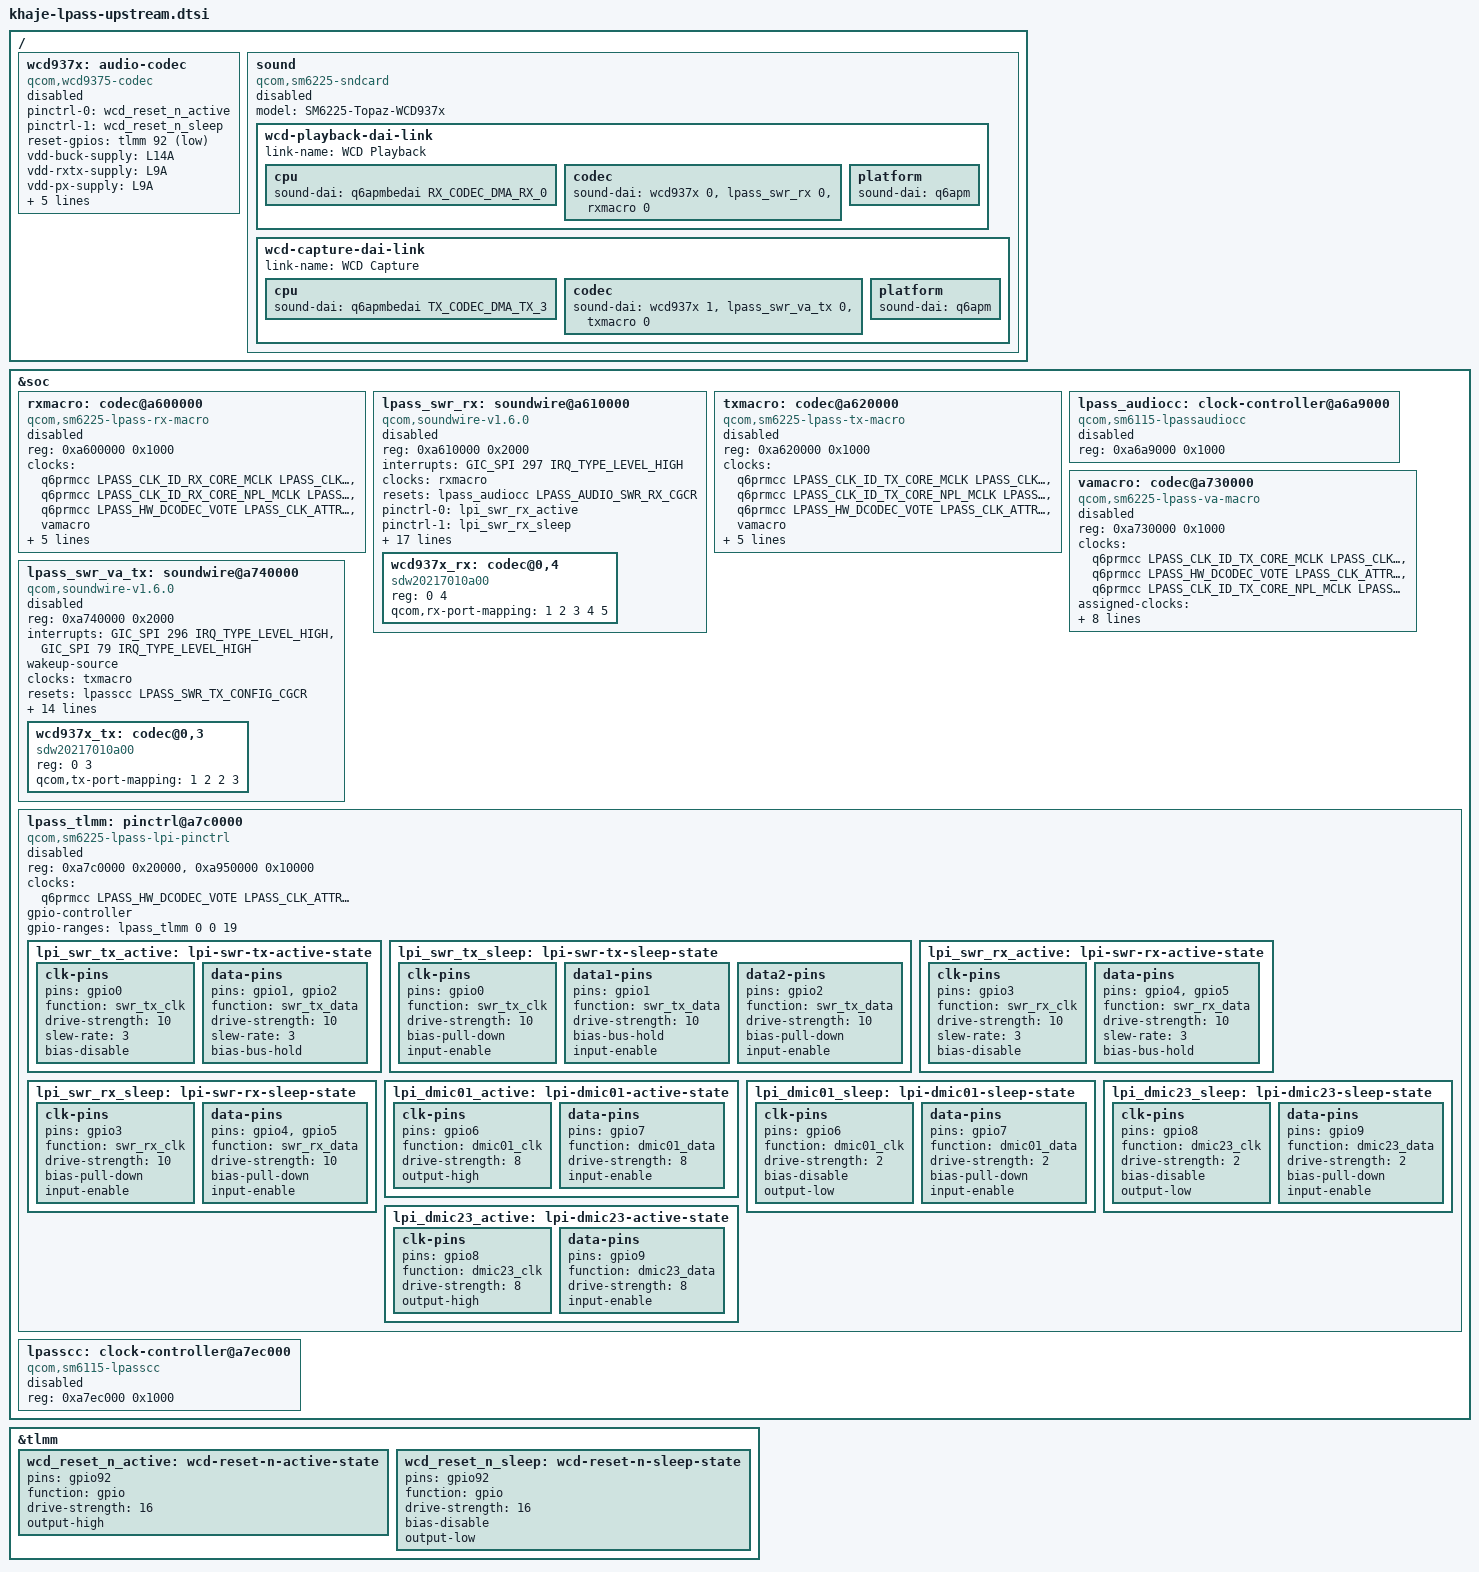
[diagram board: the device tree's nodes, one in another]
/* SPDX-License-Identifier: GPL-2.0-only */
/*
 * DTS DE TESTE — LPASS upstream (macros RX/TX/VA + SoundWire) para o
 * Khaje/topaz.
 *
 * NAO e incluido por nenhuma DTS de producao e nao e encenado por
 * tools/integrate_dts.py (que so copia device-tree/source). Serve para
 * validar estaticamente os providers de reset do patch 0029 e os
 * compatibles/matches de macro do patch 0030 contra as labels reais da
 * arvore encenada, sem ativar probe de macro, SoundWire ou codec.
 * Todos os nos ficam "disabled".
 *
 * Uso manual: incluir depois de khaje.dtsi/khaje-idp-nopmi.dtsi e de
 * khaje-adsp-upstream.dtsi (que define &q6prmcc) numa DTS de teste e
 * compilar com dtc. Nao usar junto do overlay de audio vendor Bengal
 * como modelo de ativacao: os dois descrevem o mesmo hardware LPASS.
 * Auditoria em docs/audio-port-audit.md.
 *
 * Traducao feita neste fragmento:
 *   - MMIO das macros e versao/IRQs/portas logicas SoundWire vem do
 *     overlay vendor Bengal: RX 0xa600000, TX 0xa620000,
 *     VA 0xa730000; SWR RX 0xa610000/SPI 297 e SWR VA_TX
 *     0xa740000/SPI 296+79, ambos qcom,soundwire-v1.6.0;
 *   - a topologia de clocks e os arrays qcom,ports-* seguem o DTS
 *     upstream Agatti/SM6115, trocando apenas o provider legado
 *     &q6afecc pelo &q6prmcc ja modelado no prototipo AudioReach.
 *     Os IDs simbolicos LPASS_CLK_ID_* sao os mesmos e mapeiam no
 *     Q6PRM para RX 0x30e/0x30f e TX 0x30c/0x30d;
 *   - os resets usam os CGCRs do patch 0029. Os offsets 0x98/0x100
 *     conferem com qcom,swrm-hctl-reg = 0xa6a9098/0xa7ec100 do
 *     overlay vendor sobre as bases 0xa6a9000/0xa7ec000;
 *   - VA recebe qcom,dmic-sample-rate = 600000, valor vendor e unico
 *     dos tres drivers que o driver upstream realmente le;
 *   - o patch 0031 modela o LPI TLMM em 0xa7c0000/0xa950000 com os
 *     estados SoundWire ativos/sleep traduzidos do FDT Topaz:
 *     TX em gpio0-2 e RX em gpio3-5, func1 virando
 *     swr_tx e swr_rx, slew-rate 3 e drive-strength 10 ativos.
 *     O clock "audio" usa o voto DCODEC do &q6prmcc, como no
 *     binding SM6115 sobre o provider AudioReach local. Os
 *     estados DMIC gpio6-9 (dmic01/dmic23 clk e data) seguem os
 *     valores active/sleep do FDT e ficam ligados a VA;
 *   - os slaves WCD937x usam os IDs decodificados dos reg vendor
 *     <0x0a 0x01170224> (RX) e <0x0a 0x01170223> (TX): fabricante
 *     0x0217, parte 0x010a, versao 2 e unique-id 4/3, ou seja
 *     codec@0,4 e codec@0,3 com compatible sdw20217010a00. O pai
 *     usa reset no TLMM GPIO 92, supplies L9A (rxtx/px) e L14A
 *     (buck) e micbias 1-3 em 2700 mV do overlay Xiaomi;
 *   - o patch 0032 liga a maquina generica AudioReach sc8280xp ao
 *     compatible qcom,sm6225-sndcard. O no sound abaixo descreve
 *     somente os backends WCD Playback e WCD Capture sobre o
 *     &q6apmbedai, no mesmo formato das placas QCM6490 com WCD9370.
 *
 * Bloqueios conhecidos antes de qualquer ativacao:
 *   - o overlay vendor tambem declara clocks VA dedicados 0x307/0x308,
 *     mas o no VA usa qcom,default-clk-id = <TX_CORE_CLK> e o modelo
 *     upstream SM6115 alimenta VA com TX core/NPL. Essa e uma hipotese
 *     forte de topologia, nao uma prova de runtime no SM6225;
 *   - os estados LPI de DMIC (gpio6-9) sao modelados e ligados a
 *     VA, mas as rotas de microfone/micbias entre VA, TX e WCD e o
 *     ID de backend do link VA seguem abertos; sem isso a VA nao
 *     entra no no sound;
 *   - o pai WCD e modelado como wcd9375 com fallback wcd9370 por
 *     inferencia dos overlays Khaje "nowcd9375"; o FDT Topaz so diz
 *     wcd937x e o driver distingue o chip por registrador, mas a
 *     identidade do silicio nao esta confirmada. O rail upstream
 *     vdd-mic-bias nao foi identificado no Topaz (o vendor lista so
 *     rxtx/px/buck), micbias4 nao e inventado e o map estatico TX
 *     <1 2 2 3> nao reproduz o mapa por canal vendor. Mesmo com a
 *     maquina modelada, sem fechar isso, rotas, amplificadores, o
 *     link VA e a topologia AudioReach do firmware, nao ha card
 *     de som utilizavel;
 *   - o ADSP/GPR/Q6PRM do fragmento vizinho continua desabilitado e
 *     sem boot/probe em hardware. Compilar este DTS nao valida os
 *     votos de clock no firmware nem a enumeracao SoundWire.
 */

#include <dt-bindings/clock/qcom,sm6115-lpasscc.h>
#include <dt-bindings/gpio/gpio.h>
#include <dt-bindings/interrupt-controller/arm-gic.h>
#include <dt-bindings/interrupt-controller/irq.h>
#include <dt-bindings/sound/qcom,q6afe.h>
#include <dt-bindings/sound/qcom,q6dsp-lpass-ports.h>

&soc {
	rxmacro: codec@a600000 {
		compatible = "qcom,sm6225-lpass-rx-macro",
			     "qcom,sm6115-lpass-rx-macro";
		reg = <0xa600000 0x1000>;

		clocks = <&q6prmcc LPASS_CLK_ID_RX_CORE_MCLK
				LPASS_CLK_ATTRIBUTE_COUPLE_NO>,
			 <&q6prmcc LPASS_CLK_ID_RX_CORE_NPL_MCLK
				LPASS_CLK_ATTRIBUTE_COUPLE_NO>,
			 <&q6prmcc LPASS_HW_DCODEC_VOTE
				LPASS_CLK_ATTRIBUTE_COUPLE_NO>,
			 <&vamacro>;
		clock-names = "mclk", "npl", "dcodec", "fsgen";
		assigned-clocks = <&q6prmcc LPASS_CLK_ID_RX_CORE_MCLK
					LPASS_CLK_ATTRIBUTE_COUPLE_NO>,
				  <&q6prmcc LPASS_CLK_ID_RX_CORE_NPL_MCLK
					LPASS_CLK_ATTRIBUTE_COUPLE_NO>;
		assigned-clock-rates = <22579200>, <22579200>;

		#clock-cells = <0>;
		clock-output-names = "mclk";
		#sound-dai-cells = <1>;

		status = "disabled";
	};

	lpass_swr_rx: soundwire@a610000 {
		compatible = "qcom,soundwire-v1.6.0";
		reg = <0xa610000 0x2000>;
		interrupts = <GIC_SPI 297 IRQ_TYPE_LEVEL_HIGH>;

		clocks = <&rxmacro>;
		clock-names = "iface";
		resets = <&lpass_audiocc LPASS_AUDIO_SWR_RX_CGCR>;
		reset-names = "swr_audio_cgcr";

		pinctrl-0 = <&lpi_swr_rx_active>;
		pinctrl-1 = <&lpi_swr_rx_sleep>;
		pinctrl-names = "default", "sleep";

		label = "RX";
		qcom,din-ports = <0>;
		qcom,dout-ports = <5>;

		qcom,ports-sinterval-low =
			/bits/ 8 <0x03 0x1f 0x1f 0x07 0x00>;
		qcom,ports-offset1 =
			/bits/ 8 <0x00 0x00 0x0b 0x01 0x00>;
		qcom,ports-offset2 =
			/bits/ 8 <0x00 0x00 0x0b 0x00 0x00>;
		qcom,ports-hstart =
			/bits/ 8 <0xff 0x03 0xff 0xff 0xff>;
		qcom,ports-hstop =
			/bits/ 8 <0xff 0x06 0xff 0xff 0xff>;
		qcom,ports-word-length =
			/bits/ 8 <0x01 0x07 0x04 0xff 0xff>;
		qcom,ports-block-pack-mode =
			/bits/ 8 <0xff 0x00 0x01 0xff 0xff>;
		qcom,ports-block-group-count =
			/bits/ 8 <0xff 0xff 0xff 0xff 0x00>;
		qcom,ports-lane-control =
			/bits/ 8 <0x01 0x00 0x00 0x00 0x00>;

		#sound-dai-cells = <1>;
		#address-cells = <2>;
		#size-cells = <0>;

		status = "disabled";

		wcd937x_rx: codec@0,4 {
			compatible = "sdw20217010a00";
			reg = <0 4>;
			qcom,rx-port-mapping = <1 2 3 4 5>;
		};
	};

	txmacro: codec@a620000 {
		compatible = "qcom,sm6225-lpass-tx-macro",
			     "qcom,sm6115-lpass-tx-macro";
		reg = <0xa620000 0x1000>;

		clocks = <&q6prmcc LPASS_CLK_ID_TX_CORE_MCLK
				LPASS_CLK_ATTRIBUTE_COUPLE_NO>,
			 <&q6prmcc LPASS_CLK_ID_TX_CORE_NPL_MCLK
				LPASS_CLK_ATTRIBUTE_COUPLE_NO>,
			 <&q6prmcc LPASS_HW_DCODEC_VOTE
				LPASS_CLK_ATTRIBUTE_COUPLE_NO>,
			 <&vamacro>;
		clock-names = "mclk", "npl", "dcodec", "fsgen";
		assigned-clocks = <&q6prmcc LPASS_CLK_ID_TX_CORE_MCLK
					LPASS_CLK_ATTRIBUTE_COUPLE_NO>,
				  <&q6prmcc LPASS_CLK_ID_TX_CORE_NPL_MCLK
					LPASS_CLK_ATTRIBUTE_COUPLE_NO>;
		assigned-clock-rates = <19200000>, <19200000>;

		#clock-cells = <0>;
		clock-output-names = "mclk";
		#sound-dai-cells = <1>;

		status = "disabled";
	};

	lpass_audiocc: clock-controller@a6a9000 {
		compatible = "qcom,sm6115-lpassaudiocc";
		reg = <0xa6a9000 0x1000>;
		#reset-cells = <1>;

		status = "disabled";
	};

	vamacro: codec@a730000 {
		compatible = "qcom,sm6225-lpass-va-macro",
			     "qcom,sm6115-lpass-va-macro";
		reg = <0xa730000 0x1000>;

		clocks = <&q6prmcc LPASS_CLK_ID_TX_CORE_MCLK
				LPASS_CLK_ATTRIBUTE_COUPLE_NO>,
			 <&q6prmcc LPASS_HW_DCODEC_VOTE
				LPASS_CLK_ATTRIBUTE_COUPLE_NO>,
			 <&q6prmcc LPASS_CLK_ID_TX_CORE_NPL_MCLK
				LPASS_CLK_ATTRIBUTE_COUPLE_NO>;
		clock-names = "mclk", "dcodec", "npl";
		assigned-clocks = <&q6prmcc LPASS_CLK_ID_TX_CORE_MCLK
					LPASS_CLK_ATTRIBUTE_COUPLE_NO>,
				  <&q6prmcc LPASS_CLK_ID_TX_CORE_NPL_MCLK
					LPASS_CLK_ATTRIBUTE_COUPLE_NO>;
		assigned-clock-rates = <19200000>, <19200000>;

		#clock-cells = <0>;
		clock-output-names = "fsgen";
		#sound-dai-cells = <1>;
		qcom,dmic-sample-rate = <600000>;

		pinctrl-0 = <&lpi_dmic01_active>, <&lpi_dmic23_active>;
		pinctrl-1 = <&lpi_dmic01_sleep>, <&lpi_dmic23_sleep>;
		pinctrl-names = "default", "sleep";

		status = "disabled";
	};

	lpass_swr_va_tx: soundwire@a740000 {
		compatible = "qcom,soundwire-v1.6.0";
		reg = <0xa740000 0x2000>;
		interrupts = <GIC_SPI 296 IRQ_TYPE_LEVEL_HIGH>,
			     <GIC_SPI 79 IRQ_TYPE_LEVEL_HIGH>;
		interrupt-names = "core", "wakeup";
		wakeup-source;

		clocks = <&txmacro>;
		clock-names = "iface";
		resets = <&lpasscc LPASS_SWR_TX_CONFIG_CGCR>;
		reset-names = "swr_audio_cgcr";

		pinctrl-0 = <&lpi_swr_tx_active>;
		pinctrl-1 = <&lpi_swr_tx_sleep>;
		pinctrl-names = "default", "sleep";

		label = "VA_TX";
		qcom,din-ports = <3>;
		qcom,dout-ports = <0>;

		qcom,ports-sinterval-low =
			/bits/ 8 <0x03 0x03 0x03>;
		qcom,ports-offset1 =
			/bits/ 8 <0x01 0x02 0x01>;
		qcom,ports-offset2 =
			/bits/ 8 <0x00 0x00 0x00>;
		qcom,ports-hstart =
			/bits/ 8 <0xff 0xff 0xff>;
		qcom,ports-hstop =
			/bits/ 8 <0xff 0xff 0xff>;
		qcom,ports-word-length =
			/bits/ 8 <0xff 0xff 0xff>;
		qcom,ports-block-pack-mode =
			/bits/ 8 <0xff 0xff 0xff>;
		qcom,ports-block-group-count =
			/bits/ 8 <0xff 0xff 0xff>;
		qcom,ports-lane-control =
			/bits/ 8 <0x00 0x00 0x00>;

		#sound-dai-cells = <1>;
		#address-cells = <2>;
		#size-cells = <0>;

		status = "disabled";

		wcd937x_tx: codec@0,3 {
			compatible = "sdw20217010a00";
			reg = <0 3>;
			qcom,tx-port-mapping = <1 2 2 3>;
		};
	};

	lpass_tlmm: pinctrl@a7c0000 {
		compatible = "qcom,sm6225-lpass-lpi-pinctrl",
			     "qcom,sm6115-lpass-lpi-pinctrl";
		reg = <0xa7c0000 0x20000>,
		      <0xa950000 0x10000>;

		clocks = <&q6prmcc LPASS_HW_DCODEC_VOTE
					LPASS_CLK_ATTRIBUTE_COUPLE_NO>;
		clock-names = "audio";

		gpio-controller;
		#gpio-cells = <2>;
		gpio-ranges = <&lpass_tlmm 0 0 19>;

		status = "disabled";

		lpi_swr_tx_active: lpi-swr-tx-active-state {
			clk-pins {
				pins = "gpio0";
				function = "swr_tx_clk";
				drive-strength = <10>;
				slew-rate = <3>;
				bias-disable;
			};

			data-pins {
				pins = "gpio1", "gpio2";
				function = "swr_tx_data";
				drive-strength = <10>;
				slew-rate = <3>;
				bias-bus-hold;
			};
		};

		lpi_swr_tx_sleep: lpi-swr-tx-sleep-state {
			clk-pins {
				pins = "gpio0";
				function = "swr_tx_clk";
				drive-strength = <10>;
				bias-pull-down;
				input-enable;
			};

			data1-pins {
				pins = "gpio1";
				function = "swr_tx_data";
				drive-strength = <10>;
				bias-bus-hold;
				input-enable;
			};

			data2-pins {
				pins = "gpio2";
				function = "swr_tx_data";
				drive-strength = <10>;
				bias-pull-down;
				input-enable;
			};
		};

		lpi_swr_rx_active: lpi-swr-rx-active-state {
			clk-pins {
				pins = "gpio3";
				function = "swr_rx_clk";
				drive-strength = <10>;
				slew-rate = <3>;
				bias-disable;
			};

			data-pins {
				pins = "gpio4", "gpio5";
				function = "swr_rx_data";
				drive-strength = <10>;
				slew-rate = <3>;
				bias-bus-hold;
			};
		};

		lpi_swr_rx_sleep: lpi-swr-rx-sleep-state {
			clk-pins {
				pins = "gpio3";
				function = "swr_rx_clk";
				drive-strength = <10>;
				bias-pull-down;
				input-enable;
			};

			data-pins {
				pins = "gpio4", "gpio5";
				function = "swr_rx_data";
				drive-strength = <10>;
				bias-pull-down;
				input-enable;
			};
		};
		lpi_dmic01_active: lpi-dmic01-active-state {
			clk-pins {
				pins = "gpio6";
				function = "dmic01_clk";
				drive-strength = <8>;
				output-high;
			};

			data-pins {
				pins = "gpio7";
				function = "dmic01_data";
				drive-strength = <8>;
				input-enable;
			};
		};

		lpi_dmic01_sleep: lpi-dmic01-sleep-state {
			clk-pins {
				pins = "gpio6";
				function = "dmic01_clk";
				drive-strength = <2>;
				bias-disable;
				output-low;
			};

			data-pins {
				pins = "gpio7";
				function = "dmic01_data";
				drive-strength = <2>;
				bias-pull-down;
				input-enable;
			};
		};

		lpi_dmic23_active: lpi-dmic23-active-state {
			clk-pins {
				pins = "gpio8";
				function = "dmic23_clk";
				drive-strength = <8>;
				output-high;
			};

			data-pins {
				pins = "gpio9";
				function = "dmic23_data";
				drive-strength = <8>;
				input-enable;
			};
		};

		lpi_dmic23_sleep: lpi-dmic23-sleep-state {
			clk-pins {
				pins = "gpio8";
				function = "dmic23_clk";
				drive-strength = <2>;
				bias-disable;
				output-low;
			};

			data-pins {
				pins = "gpio9";
				function = "dmic23_data";
				drive-strength = <2>;
				bias-pull-down;
				input-enable;
			};
		};
	};

	lpasscc: clock-controller@a7ec000 {
		compatible = "qcom,sm6115-lpasscc";
		reg = <0xa7ec000 0x1000>;
		#reset-cells = <1>;

		status = "disabled";
	};
};

/ {
	wcd937x: audio-codec {
		compatible = "qcom,wcd9375-codec", "qcom,wcd9370-codec";

		pinctrl-0 = <&wcd_reset_n_active>;
		pinctrl-1 = <&wcd_reset_n_sleep>;
		pinctrl-names = "default", "sleep";

		reset-gpios = <&tlmm 92 GPIO_ACTIVE_LOW>;

		vdd-buck-supply = <&L14A>;
		vdd-rxtx-supply = <&L9A>;
		vdd-px-supply = <&L9A>;

		qcom,micbias1-microvolt = <2700000>;
		qcom,micbias2-microvolt = <2700000>;
		qcom,micbias3-microvolt = <2700000>;

		qcom,rx-device = <&wcd937x_rx>;
		qcom,tx-device = <&wcd937x_tx>;

		#sound-dai-cells = <1>;
		status = "disabled";
	};

	sound: sound {
		compatible = "qcom,sm6225-sndcard";
		model = "SM6225-Topaz-WCD937x";
		status = "disabled";

		wcd-playback-dai-link {
			link-name = "WCD Playback";

			cpu {
				sound-dai = <&q6apmbedai RX_CODEC_DMA_RX_0>;
			};

			codec {
				sound-dai = <&wcd937x 0>, <&lpass_swr_rx 0>,
					    <&rxmacro 0>;
			};

			platform {
				sound-dai = <&q6apm>;
			};
		};

		wcd-capture-dai-link {
			link-name = "WCD Capture";

			cpu {
				sound-dai = <&q6apmbedai TX_CODEC_DMA_TX_3>;
			};

			codec {
				sound-dai = <&wcd937x 1>, <&lpass_swr_va_tx 0>,
					    <&txmacro 0>;
			};

			platform {
				sound-dai = <&q6apm>;
			};
		};
	};
};

&tlmm {
	wcd_reset_n_active: wcd-reset-n-active-state {
		pins = "gpio92";
		function = "gpio";
		drive-strength = <16>;
		output-high;
	};

	wcd_reset_n_sleep: wcd-reset-n-sleep-state {
		pins = "gpio92";
		function = "gpio";
		drive-strength = <16>;
		bias-disable;
		output-low;
	};
};
